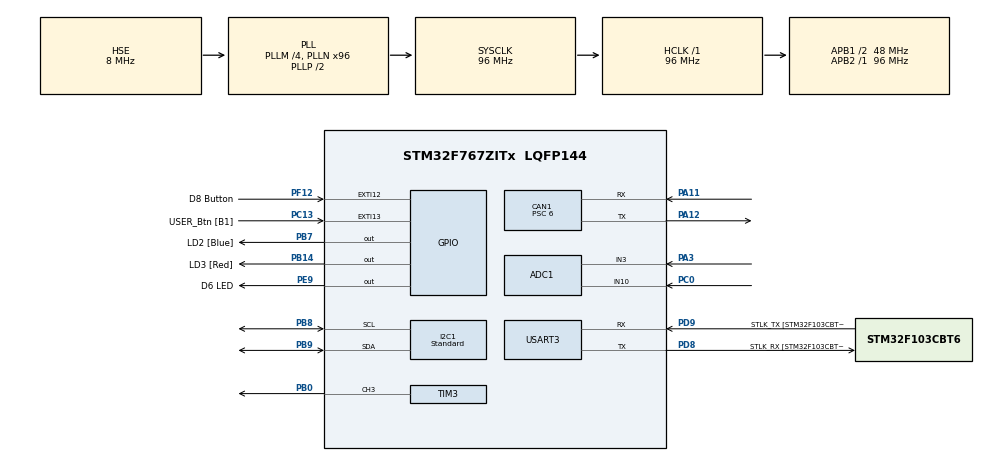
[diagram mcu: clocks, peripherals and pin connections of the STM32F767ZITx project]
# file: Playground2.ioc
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ADC1.Channel-0\#ChannelRegularConversion=ADC_CHANNEL_3
ADC1.NbrOfConversionFlag=1
ADC1.Rank-0\#ChannelRegularConversion=1
ADC1.SamplingTime-0\#ChannelRegularConversion=ADC_SAMPLETIME_3CYCLES
ADC1.master=1
CAN1.BS1=CAN_BS1_11TQ
CAN1.BS2=CAN_BS2_4TQ
CAN1.CalculateBaudRate=500000
CAN1.CalculateTimeBit=2000
CAN1.CalculateTimeQuantum=125.0
CAN1.Mode=CAN_MODE_LOOPBACK
CAN1.Prescaler=6
CORTEX_M7.default_mode_Activation=1
I2C1.I2C_Speed_Mode=I2C_Standard
I2C1.Speed=100
I2C1.Timing=0x00303D5B
Mcu.Family=STM32F7
Mcu.Name=STM32F767ZITx
Mcu.Package=LQFP144
NVIC.CAN1_RX0_IRQn=true\:0\:0\:false\:false\:true\:true\:true\:true
NVIC.CAN1_TX_IRQn=true\:0\:0\:false\:false\:true\:true\:true\:true
NVIC.EXTI15_10_IRQn=true\:0\:0\:false\:false\:true\:true\:true\:true
NVIC.PriorityGroup=NVIC_PRIORITYGROUP_4
NVIC.TIM6_DAC_IRQn=true\:0\:0\:false\:false\:true\:true\:true\:true
PA11.GPIO_PuPd=GPIO_PULLUP
PA11.Mode=CAN_Activate
PA11.Signal=CAN1_RX
PA12.Mode=CAN_Activate
PA12.Signal=CAN1_TX
PA13.GPIO_Label=TMS
PA13.Mode=Serial_Wire
PA13.Signal=SYS_JTMS-SWDIO
PA14.GPIO_Label=TCK
PA14.Mode=Serial_Wire
PA14.Signal=SYS_JTCK-SWCLK
PA3.Signal=ADCx_IN3
PB0.Signal=S_TIM3_CH3
PB14.GPIO_Label=LD3 [Red]
PB14.Signal=GPIO_Output
PB3.GPIO_Label=SWO
PB3.Signal=SYS_JTDO-SWO
PB7.GPIO_Label=LD2 [Blue]
PB7.Signal=GPIO_Output
PB8.Mode=I2C
PB8.Signal=I2C1_SCL
PB9.Mode=I2C
PB9.Signal=I2C1_SDA
PC0.Signal=ADCx_IN10
PC13.GPIO_Label=USER_Btn [B1]
PC13.Signal=GPXTI13
PC14/OSC32_IN.Mode=LSE-External-Oscillator
PC14/OSC32_IN.Signal=RCC_OSC32_IN
PC15/OSC32_OUT.Mode=LSE-External-Oscillator
PC15/OSC32_OUT.Signal=RCC_OSC32_OUT
PD8.GPIO_Label=STLK_RX [STM32F103CBT6_PA3]
PD8.Mode=Asynchronous
PD8.Signal=USART3_TX
PD9.GPIO_Label=STLK_TX [STM32F103CBT6_PA2]
PD9.Mode=Asynchronous
PD9.Signal=USART3_RX
PE9.GPIO_Label=D6 LED
PE9.Signal=GPIO_Output
PF12.GPIO_Label=D8 Button
PF12.GPIO_PuPd=GPIO_PULLUP
PF12.Signal=GPXTI12
PH0/OSC_IN.GPIO_Label=MCO [STM32F103CBT6_PA8]
PH0/OSC_IN.Mode=HSE-External-Clock-Source
PH0/OSC_IN.Signal=RCC_OSC_IN
PH1/OSC_OUT.Mode=HSE-External-Clock-Source
PH1/OSC_OUT.Signal=RCC_OSC_OUT
ProjectManager.HeapSize=0x200
ProjectManager.StackSize=0x400
ProjectManager.TargetToolchain=CMake
RCC.48MHZClocksFreq_Value=24000000
RCC.AHBFreq_Value=96000000
RCC.APB1CLKDivider=RCC_HCLK_DIV2
RCC.APB1Freq_Value=48000000
RCC.APB1TimFreq_Value=96000000
RCC.APB2Freq_Value=96000000
RCC.APB2TimFreq_Value=96000000
RCC.CortexFreq_Value=96000000
RCC.HCLKFreq_Value=96000000
RCC.HSE_VALUE=8000000
RCC.HSI_VALUE=16000000
RCC.I2C1CLockSelection=RCC_I2C1CLKSOURCE_HSI
RCC.PLLM=4
RCC.PLLMUL=RCC_PLL_MUL9
RCC.PLLN=96
RCC.PLLQ=4
RCC.PLLSourceVirtual=RCC_PLLSOURCE_HSE
RCC.PRESCALERUSB=RCC_USBCLKSOURCE_PLL_DIV1_5
RCC.SYSCLKFreq_VALUE=96000000
RCC.SYSCLKSource=RCC_SYSCLKSOURCE_PLLCLK
RCC.SYSCLKSourceVirtual=RCC_SYSCLKSOURCE_PLLCLK
RCC.USBFreq_Value=48000000
RCC.VCOOutputFreq_Value=192000000
SH.ADCx_IN10.0=ADC1_IN10,IN10
SH.ADCx_IN3.0=ADC1_IN3,IN3
SH.S_TIM3_CH3.0=TIM3_CH3,PWM Generation3 CH3
TIM3.Channel-PWM\ Generation3\ CH3=TIM_CHANNEL_3
TIM3.Period=999
TIM3.Prescaler=95
TIM6.AutoReloadPreload=TIM_AUTORELOAD_PRELOAD_ENABLE
TIM6.Period=99
TIM6.Prescaler=9599
USART3.VirtualMode-Asynchronous=VM_ASYNC
VP_TIM6_VS_ClockSourceINT.Mode=Enable_Timer
board=NUCLEO-F767ZI

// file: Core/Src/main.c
/* USER CODE BEGIN Header */
/**
  ******************************************************************************
  * @file           : main.c
  * @brief          : Main program body
  ******************************************************************************
  * @attention
  *
  * Copyright (c) 2026 STMicroelectronics.
  * All rights reserved.
  *
  * This software is licensed under terms that can be found in the LICENSE file
  * in the root directory of this software component.
  * If no LICENSE file comes with this software, it is provided AS-IS.
  *
  ******************************************************************************
  */
/* USER CODE END Header */
#include "main.h"

/* USER CODE BEGIN Includes */
#include "AppFacade.h"
/* USER CODE END Includes */

ADC_HandleTypeDef hadc1;

CAN_HandleTypeDef hcan1;

I2C_HandleTypeDef hi2c1;

TIM_HandleTypeDef htim3;
TIM_HandleTypeDef htim6;

UART_HandleTypeDef huart3;

void SystemClock_Config(void);
static void MPU_Config(void);
static void MX_GPIO_Init(void);
static void MX_USART3_UART_Init(void);
static void MX_TIM6_Init(void);
static void MX_TIM3_Init(void);
static void MX_CAN1_Init(void);
static void MX_ADC1_Init(void);
static void MX_I2C1_Init(void);

int main(void)
{

  /* MPU Configuration--------------------------------------------------------*/
  MPU_Config();

  /* MCU Configuration--------------------------------------------------------*/

  /* Reset of all peripherals, Initializes the Flash interface and the Systick. */
  HAL_Init();

  /* Configure the system clock */
  SystemClock_Config();

  /* Initialize all configured peripherals */
  MX_GPIO_Init();
  MX_USART3_UART_Init();
  MX_TIM6_Init();
  MX_TIM3_Init();
  MX_CAN1_Init();
  MX_ADC1_Init();
  MX_I2C1_Init();
  /* USER CODE BEGIN 2 */
  app_init(&hcan1, &htim3, &htim6, &huart3, &hadc1);
  /* USER CODE END 2 */

  /* Infinite loop */
  while (1)
  {

    /* USER CODE BEGIN 3 */
    app_run();
  }
  /* USER CODE END 3 */
}

void SystemClock_Config(void)
{
  RCC_OscInitTypeDef RCC_OscInitStruct = {0};
  RCC_ClkInitTypeDef RCC_ClkInitStruct = {0};

  /** Configure LSE Drive Capability
  */
  HAL_PWR_EnableBkUpAccess();

  /** Configure the main internal regulator output voltage
  */
  __HAL_RCC_PWR_CLK_ENABLE();
  __HAL_PWR_VOLTAGESCALING_CONFIG(PWR_REGULATOR_VOLTAGE_SCALE3);

  /** Initializes the RCC Oscillators according to the specified parameters
  * in the RCC_OscInitTypeDef structure.
  */
  RCC_OscInitStruct.OscillatorType = RCC_OSCILLATORTYPE_HSI|RCC_OSCILLATORTYPE_HSE;
  RCC_OscInitStruct.HSEState = RCC_HSE_BYPASS;
  RCC_OscInitStruct.HSIState = RCC_HSI_ON;
  RCC_OscInitStruct.HSICalibrationValue = RCC_HSICALIBRATION_DEFAULT;
  RCC_OscInitStruct.PLL.PLLState = RCC_PLL_ON;
  RCC_OscInitStruct.PLL.PLLSource = RCC_PLLSOURCE_HSE;
  RCC_OscInitStruct.PLL.PLLM = 4;
  RCC_OscInitStruct.PLL.PLLN = 96;
  RCC_OscInitStruct.PLL.PLLP = RCC_PLLP_DIV2;
  RCC_OscInitStruct.PLL.PLLQ = 4;
  RCC_OscInitStruct.PLL.PLLR = 2;
  if (HAL_RCC_OscConfig(&RCC_OscInitStruct) != HAL_OK)
  {
    Error_Handler();
  }

  /** Activate the Over-Drive mode
  */
  if (HAL_PWREx_EnableOverDrive() != HAL_OK)
  {
    Error_Handler();
  }

  /** Initializes the CPU, AHB and APB buses clocks
  */
  RCC_ClkInitStruct.ClockType = RCC_CLOCKTYPE_HCLK|RCC_CLOCKTYPE_SYSCLK
                              |RCC_CLOCKTYPE_PCLK1|RCC_CLOCKTYPE_PCLK2;
  RCC_ClkInitStruct.SYSCLKSource = RCC_SYSCLKSOURCE_PLLCLK;
  RCC_ClkInitStruct.AHBCLKDivider = RCC_SYSCLK_DIV1;
  RCC_ClkInitStruct.APB1CLKDivider = RCC_HCLK_DIV2;
  RCC_ClkInitStruct.APB2CLKDivider = RCC_HCLK_DIV1;

  if (HAL_RCC_ClockConfig(&RCC_ClkInitStruct, FLASH_LATENCY_3) != HAL_OK)
  {
    Error_Handler();
  }
}

static void MX_ADC1_Init(void)
{

  ADC_ChannelConfTypeDef sConfig = {0};

  /** Configure the global features of the ADC (Clock, Resolution, Data Alignment and number of conversion)
  */
  hadc1.Instance = ADC1;
  hadc1.Init.ClockPrescaler = ADC_CLOCK_SYNC_PCLK_DIV4;
  hadc1.Init.Resolution = ADC_RESOLUTION_12B;
  hadc1.Init.ScanConvMode = ADC_SCAN_DISABLE;
  hadc1.Init.ContinuousConvMode = DISABLE;
  hadc1.Init.DiscontinuousConvMode = DISABLE;
  hadc1.Init.ExternalTrigConvEdge = ADC_EXTERNALTRIGCONVEDGE_NONE;
  hadc1.Init.ExternalTrigConv = ADC_SOFTWARE_START;
  hadc1.Init.DataAlign = ADC_DATAALIGN_RIGHT;
  hadc1.Init.NbrOfConversion = 1;
  hadc1.Init.DMAContinuousRequests = DISABLE;
  hadc1.Init.EOCSelection = ADC_EOC_SINGLE_CONV;
  if (HAL_ADC_Init(&hadc1) != HAL_OK)
  {
    Error_Handler();
  }

  /** Configure for the selected ADC regular channel its corresponding rank in the sequencer and its sample time.
  */
  sConfig.Channel = ADC_CHANNEL_3;
  sConfig.Rank = ADC_REGULAR_RANK_1;
  sConfig.SamplingTime = ADC_SAMPLETIME_3CYCLES;
  if (HAL_ADC_ConfigChannel(&hadc1, &sConfig) != HAL_OK)
  {
    Error_Handler();
  }

}

static void MX_CAN1_Init(void)
{

  hcan1.Instance = CAN1;
  hcan1.Init.Prescaler = 6;
  hcan1.Init.Mode = CAN_MODE_LOOPBACK;
  hcan1.Init.SyncJumpWidth = CAN_SJW_1TQ;
  hcan1.Init.TimeSeg1 = CAN_BS1_11TQ;
  hcan1.Init.TimeSeg2 = CAN_BS2_4TQ;
  hcan1.Init.TimeTriggeredMode = DISABLE;
  hcan1.Init.AutoBusOff = DISABLE;
  hcan1.Init.AutoWakeUp = DISABLE;
  hcan1.Init.AutoRetransmission = DISABLE;
  hcan1.Init.ReceiveFifoLocked = DISABLE;
  hcan1.Init.TransmitFifoPriority = DISABLE;
  if (HAL_CAN_Init(&hcan1) != HAL_OK)
  {
    Error_Handler();
  }

}

static void MX_I2C1_Init(void)
{

  hi2c1.Instance = I2C1;
  hi2c1.Init.Timing = 0x00303D5B;
  hi2c1.Init.OwnAddress1 = 0;
  hi2c1.Init.AddressingMode = I2C_ADDRESSINGMODE_7BIT;
  hi2c1.Init.DualAddressMode = I2C_DUALADDRESS_DISABLE;
  hi2c1.Init.OwnAddress2 = 0;
  hi2c1.Init.OwnAddress2Masks = I2C_OA2_NOMASK;
  hi2c1.Init.GeneralCallMode = I2C_GENERALCALL_DISABLE;
  hi2c1.Init.NoStretchMode = I2C_NOSTRETCH_DISABLE;
  if (HAL_I2C_Init(&hi2c1) != HAL_OK)
  {
    Error_Handler();
  }

  /** Configure Analogue filter
  */
  if (HAL_I2CEx_ConfigAnalogFilter(&hi2c1, I2C_ANALOGFILTER_ENABLE) != HAL_OK)
  {
    Error_Handler();
  }

  /** Configure Digital filter
  */
  if (HAL_I2CEx_ConfigDigitalFilter(&hi2c1, 0) != HAL_OK)
  {
    Error_Handler();
  }

}

static void MX_TIM3_Init(void)
{

  TIM_MasterConfigTypeDef sMasterConfig = {0};
  TIM_OC_InitTypeDef sConfigOC = {0};

  htim3.Instance = TIM3;
  htim3.Init.Prescaler = 95;
  htim3.Init.CounterMode = TIM_COUNTERMODE_UP;
  htim3.Init.Period = 999;
  htim3.Init.ClockDivision = TIM_CLOCKDIVISION_DIV1;
  htim3.Init.AutoReloadPreload = TIM_AUTORELOAD_PRELOAD_DISABLE;
  if (HAL_TIM_PWM_Init(&htim3) != HAL_OK)
  {
    Error_Handler();
  }
  sMasterConfig.MasterOutputTrigger = TIM_TRGO_RESET;
  sMasterConfig.MasterSlaveMode = TIM_MASTERSLAVEMODE_DISABLE;
  if (HAL_TIMEx_MasterConfigSynchronization(&htim3, &sMasterConfig) != HAL_OK)
  {
    Error_Handler();
  }
  sConfigOC.OCMode = TIM_OCMODE_PWM1;
  sConfigOC.Pulse = 0;
  sConfigOC.OCPolarity = TIM_OCPOLARITY_HIGH;
  sConfigOC.OCFastMode = TIM_OCFAST_DISABLE;
  if (HAL_TIM_PWM_ConfigChannel(&htim3, &sConfigOC, TIM_CHANNEL_3) != HAL_OK)
  {
    Error_Handler();
  }
  HAL_TIM_MspPostInit(&htim3);

}

static void MX_TIM6_Init(void)
{

  TIM_MasterConfigTypeDef sMasterConfig = {0};

  htim6.Instance = TIM6;
  htim6.Init.Prescaler = 9599;
  htim6.Init.CounterMode = TIM_COUNTERMODE_UP;
  htim6.Init.Period = 99;
  htim6.Init.AutoReloadPreload = TIM_AUTORELOAD_PRELOAD_ENABLE;
  if (HAL_TIM_Base_Init(&htim6) != HAL_OK)
  {
    Error_Handler();
  }
  sMasterConfig.MasterOutputTrigger = TIM_TRGO_RESET;
  sMasterConfig.MasterSlaveMode = TIM_MASTERSLAVEMODE_DISABLE;
  if (HAL_TIMEx_MasterConfigSynchronization(&htim6, &sMasterConfig) != HAL_OK)
  {
    Error_Handler();
  }

}

static void MX_USART3_UART_Init(void)
{

  huart3.Instance = USART3;
  huart3.Init.BaudRate = 115200;
  huart3.Init.WordLength = UART_WORDLENGTH_8B;
  huart3.Init.StopBits = UART_STOPBITS_1;
  huart3.Init.Parity = UART_PARITY_NONE;
  huart3.Init.Mode = UART_MODE_TX_RX;
  huart3.Init.HwFlowCtl = UART_HWCONTROL_NONE;
  huart3.Init.OverSampling = UART_OVERSAMPLING_16;
  huart3.Init.OneBitSampling = UART_ONE_BIT_SAMPLE_DISABLE;
  huart3.AdvancedInit.AdvFeatureInit = UART_ADVFEATURE_NO_INIT;
  if (HAL_UART_Init(&huart3) != HAL_OK)
  {
    Error_Handler();
  }

}

static void MX_GPIO_Init(void)
{
  GPIO_InitTypeDef GPIO_InitStruct = {0};

  /* GPIO Ports Clock Enable */
  __HAL_RCC_GPIOC_CLK_ENABLE();
  __HAL_RCC_GPIOH_CLK_ENABLE();
  __HAL_RCC_GPIOA_CLK_ENABLE();
  __HAL_RCC_GPIOB_CLK_ENABLE();
  __HAL_RCC_GPIOF_CLK_ENABLE();
  __HAL_RCC_GPIOE_CLK_ENABLE();
  __HAL_RCC_GPIOD_CLK_ENABLE();

  /*Configure GPIO pin Output Level */
  HAL_GPIO_WritePin(D6_LED_GPIO_Port, D6_LED_Pin, GPIO_PIN_RESET);

  /*Configure GPIO pin Output Level */
  HAL_GPIO_WritePin(GPIOB, LD3_Pin|LD2_Pin, GPIO_PIN_RESET);

  /*Configure GPIO pin : USER_Btn_Pin */
  GPIO_InitStruct.Pin = USER_Btn_Pin;
  GPIO_InitStruct.Mode = GPIO_MODE_IT_RISING;
  GPIO_InitStruct.Pull = GPIO_NOPULL;
  HAL_GPIO_Init(USER_Btn_GPIO_Port, &GPIO_InitStruct);

  /*Configure GPIO pin : D8_Button_Pin */
  GPIO_InitStruct.Pin = D8_Button_Pin;
  GPIO_InitStruct.Mode = GPIO_MODE_IT_RISING;
  GPIO_InitStruct.Pull = GPIO_PULLUP;
  HAL_GPIO_Init(D8_Button_GPIO_Port, &GPIO_InitStruct);

  /*Configure GPIO pin : D6_LED_Pin */
  GPIO_InitStruct.Pin = D6_LED_Pin;
  GPIO_InitStruct.Mode = GPIO_MODE_OUTPUT_PP;
  GPIO_InitStruct.Pull = GPIO_NOPULL;
  GPIO_InitStruct.Speed = GPIO_SPEED_FREQ_LOW;
  HAL_GPIO_Init(D6_LED_GPIO_Port, &GPIO_InitStruct);

  /*Configure GPIO pins : LD3_Pin LD2_Pin */
  GPIO_InitStruct.Pin = LD3_Pin|LD2_Pin;
  GPIO_InitStruct.Mode = GPIO_MODE_OUTPUT_PP;
  GPIO_InitStruct.Pull = GPIO_NOPULL;
  GPIO_InitStruct.Speed = GPIO_SPEED_FREQ_LOW;
  HAL_GPIO_Init(GPIOB, &GPIO_InitStruct);

  /* EXTI interrupt init*/
  HAL_NVIC_SetPriority(EXTI15_10_IRQn, 0, 0);
  HAL_NVIC_EnableIRQ(EXTI15_10_IRQn);

}

 /* MPU Configuration */

void MPU_Config(void)
{
  MPU_Region_InitTypeDef MPU_InitStruct = {0};

  /* Disables the MPU */
  HAL_MPU_Disable();

  /** Initializes and configures the Region and the memory to be protected
  */
  MPU_InitStruct.Enable = MPU_REGION_ENABLE;
  MPU_InitStruct.Number = MPU_REGION_NUMBER0;
  MPU_InitStruct.BaseAddress = 0x0;
  MPU_InitStruct.Size = MPU_REGION_SIZE_4GB;
  MPU_InitStruct.SubRegionDisable = 0x87;
  MPU_InitStruct.TypeExtField = MPU_TEX_LEVEL0;
  MPU_InitStruct.AccessPermission = MPU_REGION_NO_ACCESS;
  MPU_InitStruct.DisableExec = MPU_INSTRUCTION_ACCESS_DISABLE;
  MPU_InitStruct.IsShareable = MPU_ACCESS_SHAREABLE;
  MPU_InitStruct.IsCacheable = MPU_ACCESS_NOT_CACHEABLE;
  MPU_InitStruct.IsBufferable = MPU_ACCESS_NOT_BUFFERABLE;

  HAL_MPU_ConfigRegion(&MPU_InitStruct);
  /* Enables the MPU */
  HAL_MPU_Enable(MPU_PRIVILEGED_DEFAULT);

}

void Error_Handler(void)
{
  __disable_irq();
  while (1)
  {
  }
}
